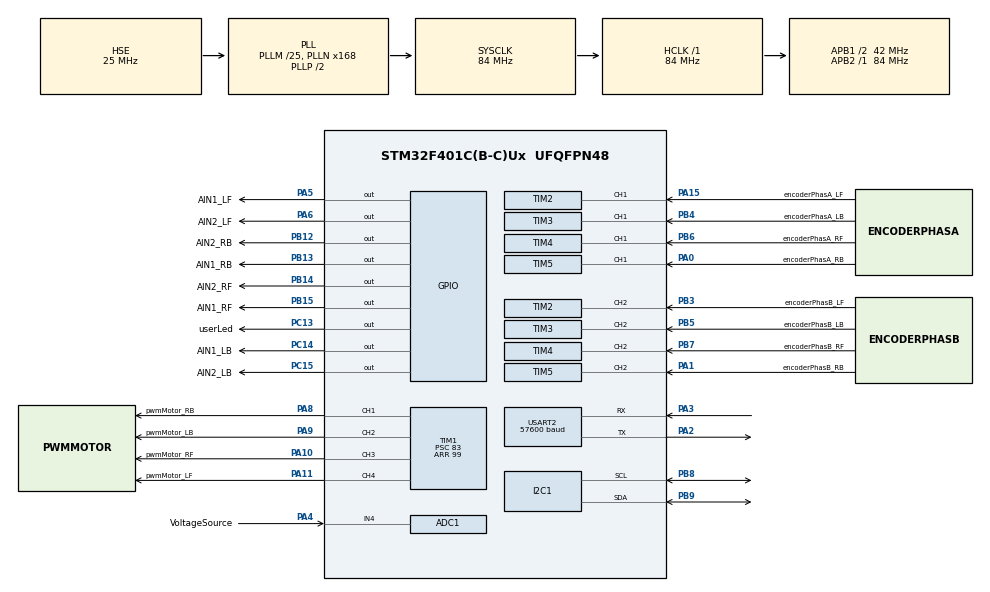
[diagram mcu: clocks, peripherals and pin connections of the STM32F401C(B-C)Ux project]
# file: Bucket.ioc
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ADC1.Channel-3\#ChannelRegularConversion=ADC_CHANNEL_4
ADC1.NbrOfConversionFlag=1
ADC1.Rank-3\#ChannelRegularConversion=1
ADC1.SamplingTime-3\#ChannelRegularConversion=ADC_SAMPLETIME_3CYCLES
ADC1.ScanConvMode=DISABLE
ADC1.master=1
I2C1.DualAddressMode=I2C_DUALADDRESS_DISABLE
Mcu.Family=STM32F4
Mcu.Name=STM32F401C(B-C)Ux
Mcu.Package=UFQFPN48
NVIC.PriorityGroup=NVIC_PRIORITYGROUP_4
NVIC.TIM1_UP_TIM10_IRQn=true\:0\:0\:false\:false\:true\:true\:true\:true
NVIC.USART2_IRQn=true\:0\:0\:false\:false\:true\:true\:true\:true
PA0-WKUP.GPIO_Label=encoderPhasA_RB
PA0-WKUP.Signal=S_TIM5_CH1
PA1.GPIO_Label=encoderPhasB_RB
PA1.Signal=S_TIM5_CH2
PA10.GPIO_Label=pwmMotor_RF
PA10.Signal=S_TIM1_CH3
PA11.GPIO_Label=pwmMotor_LF
PA11.Signal=S_TIM1_CH4
PA13.Mode=Serial_Wire
PA13.Signal=SYS_JTMS-SWDIO
PA14.Mode=Serial_Wire
PA14.Signal=SYS_JTCK-SWCLK
PA15.GPIO_Label=encoderPhasA_LF
PA15.Signal=S_TIM2_CH1_ETR
PA2.Mode=Asynchronous
PA2.Signal=USART2_TX
PA3.Mode=Asynchronous
PA3.Signal=USART2_RX
PA4.GPIO_Label=VoltageSource
PA4.Signal=ADCx_IN4
PA5.GPIO_Label=AIN1_LF
PA5.Signal=GPIO_Output
PA6.GPIO_Label=AIN2_LF
PA6.Signal=GPIO_Output
PA8.GPIO_Label=pwmMotor_RB
PA8.Signal=S_TIM1_CH1
PA9.GPIO_Label=pwmMotor_LB
PA9.Signal=S_TIM1_CH2
PB12.GPIO_Label=AIN2_RB
PB12.Signal=GPIO_Output
PB13.GPIO_Label=AIN1_RB
PB13.Signal=GPIO_Output
PB14.GPIO_Label=AIN2_RF
PB14.Signal=GPIO_Output
PB15.GPIO_Label=AIN1_RF
PB15.Signal=GPIO_Output
PB3.GPIO_Label=encoderPhasB_LF
PB3.Signal=S_TIM2_CH2
PB4.GPIO_Label=encoderPhasA_LB
PB4.Signal=S_TIM3_CH1
PB5.GPIO_Label=encoderPhasB_LB
PB5.Signal=S_TIM3_CH2
PB6.GPIO_Label=encoderPhasA_RF
PB6.Signal=S_TIM4_CH1
PB7.GPIO_Label=encoderPhasB_RF
PB7.Signal=S_TIM4_CH2
PB8.Mode=I2C
PB8.Signal=I2C1_SCL
PB9.Mode=I2C
PB9.Signal=I2C1_SDA
PC13-ANTI_TAMP.GPIO_Label=userLed
PC13-ANTI_TAMP.Signal=GPIO_Output
PC14-OSC32_IN.GPIO_Label=AIN1_LB
PC14-OSC32_IN.Signal=GPIO_Output
PC15-OSC32_OUT.GPIO_Label=AIN2_LB
PC15-OSC32_OUT.Signal=GPIO_Output
PH0\ -\ OSC_IN.Mode=HSE-External-Oscillator
PH0\ -\ OSC_IN.Signal=RCC_OSC_IN
PH1\ -\ OSC_OUT.Mode=HSE-External-Oscillator
PH1\ -\ OSC_OUT.Signal=RCC_OSC_OUT
ProjectManager.HeapSize=0x200
ProjectManager.StackSize=0x400
ProjectManager.TargetToolchain=STM32CubeIDE
RCC.48MHZClocksFreq_Value=42000000
RCC.AHBFreq_Value=84000000
RCC.APB1CLKDivider=RCC_HCLK_DIV2
RCC.APB1Freq_Value=42000000
RCC.APB1TimFreq_Value=84000000
RCC.APB2Freq_Value=84000000
RCC.APB2TimFreq_Value=84000000
RCC.CortexFreq_Value=84000000
RCC.HCLKFreq_Value=84000000
RCC.HSE_VALUE=25000000
RCC.HSI_VALUE=16000000
RCC.LSE_VALUE=32768
RCC.PLLM=25
RCC.PLLN=168
RCC.PLLSourceVirtual=RCC_PLLSOURCE_HSE
RCC.SYSCLKFreq_VALUE=84000000
RCC.SYSCLKSource=RCC_SYSCLKSOURCE_PLLCLK
RCC.VCOOutputFreq_Value=168000000
SH.ADCx_IN4.0=ADC1_IN4,IN4
SH.S_TIM1_CH1.0=TIM1_CH1,PWM Generation1 CH1
SH.S_TIM1_CH2.0=TIM1_CH2,PWM Generation2 CH2
SH.S_TIM1_CH3.0=TIM1_CH3,PWM Generation3 CH3
SH.S_TIM1_CH4.0=TIM1_CH4,PWM Generation4 CH4
SH.S_TIM2_CH1_ETR.0=TIM2_CH1,Encoder_Interface
SH.S_TIM2_CH2.0=TIM2_CH2,Encoder_Interface
SH.S_TIM3_CH1.0=TIM3_CH1,Encoder_Interface
SH.S_TIM3_CH2.0=TIM3_CH2,Encoder_Interface
SH.S_TIM4_CH1.0=TIM4_CH1,Encoder_Interface
SH.S_TIM4_CH2.0=TIM4_CH2,Encoder_Interface
SH.S_TIM5_CH1.0=TIM5_CH1,Encoder_Interface
SH.S_TIM5_CH2.0=TIM5_CH2,Encoder_Interface
TIM1.AutoReloadPreload=TIM_AUTORELOAD_PRELOAD_ENABLE
TIM1.BreakPolarity=TIM_BREAKPOLARITY_HIGH
TIM1.Channel-PWM\ Generation1\ CH1=TIM_CHANNEL_1
TIM1.Channel-PWM\ Generation2\ CH2=TIM_CHANNEL_2
TIM1.Channel-PWM\ Generation3\ CH3=TIM_CHANNEL_3
TIM1.Channel-PWM\ Generation4\ CH4=TIM_CHANNEL_4
TIM1.OCPolarity_1=TIM_OCPOLARITY_HIGH
TIM1.OCPolarity_3=TIM_OCPOLARITY_HIGH
TIM1.Period=99
TIM1.Prescaler=83
TIM1.Pulse-PWM\ Generation1\ CH1=0
TIM1.Pulse-PWM\ Generation2\ CH2=0
TIM1.Pulse-PWM\ Generation3\ CH3=0
TIM1.Pulse-PWM\ Generation4\ CH4=0
TIM10.AutoReloadPreload=TIM_AUTORELOAD_PRELOAD_ENABLE
TIM10.Period=9999
TIM10.Prescaler=83
TIM2.EncoderMode=TIM_ENCODERMODE_TI12
TIM2.IC1Filter=1
TIM2.IC2Filter=1
TIM3.EncoderMode=TIM_ENCODERMODE_TI12
TIM3.IC1Filter=1
TIM3.IC2Filter=1
TIM4.EncoderMode=TIM_ENCODERMODE_TI12
TIM4.IC1Filter=1
TIM4.IC2Filter=1
TIM5.EncoderMode=TIM_ENCODERMODE_TI12
TIM5.IC1Filter=1
TIM5.IC2Filter=1
USART2.BaudRate=57600
USART2.VirtualMode=VM_ASYNC
VP_TIM10_VS_ClockSourceINT.Mode=Enable_Timer
VP_TIM1_VS_ClockSourceINT.Mode=Internal
VP_TIM9_VS_ClockSourceINT.Mode=Internal
board=custom

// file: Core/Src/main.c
/* USER CODE BEGIN Header */
/**
 ******************************************************************************
 * @file           : main.c
 * @brief          : Main program body
 ******************************************************************************
 * @attention
 *
 * Copyright (c) 2026 STMicroelectronics.
 * All rights reserved.
 *
 * This software is licensed under terms that can be found in the LICENSE file
 * in the root directory of this software component.
 * If no LICENSE file comes with this software, it is provided AS-IS.
 *
 ******************************************************************************
 */
/* USER CODE END Header */
#include "main.h"

/* USER CODE BEGIN Includes */
#include "cpp_main.hpp"
/* USER CODE END Includes */

ADC_HandleTypeDef hadc1;

I2C_HandleTypeDef hi2c1;

TIM_HandleTypeDef htim1;
TIM_HandleTypeDef htim2;
TIM_HandleTypeDef htim3;
TIM_HandleTypeDef htim4;
TIM_HandleTypeDef htim5;
TIM_HandleTypeDef htim9;
TIM_HandleTypeDef htim10;

UART_HandleTypeDef huart2;

void SystemClock_Config(void);
static void MX_GPIO_Init(void);
static void MX_TIM1_Init(void);
static void MX_TIM3_Init(void);
static void MX_TIM4_Init(void);
static void MX_TIM5_Init(void);
static void MX_USART2_UART_Init(void);
static void MX_TIM10_Init(void);
static void MX_TIM2_Init(void);
static void MX_TIM9_Init(void);
static void MX_I2C1_Init(void);
static void MX_ADC1_Init(void);

int main(void)
{

  /* MCU Configuration--------------------------------------------------------*/

  /* Reset of all peripherals, Initializes the Flash interface and the Systick. */
  HAL_Init();

  /* Configure the system clock */
  SystemClock_Config();

  /* Initialize all configured peripherals */
  MX_GPIO_Init();
  MX_TIM1_Init();
  MX_TIM3_Init();
  MX_TIM4_Init();
  MX_TIM5_Init();
  MX_USART2_UART_Init();
  MX_TIM10_Init();
  MX_TIM2_Init();
  MX_TIM9_Init();
  MX_I2C1_Init();
  MX_ADC1_Init();
  /* USER CODE BEGIN 2 */

  cpp_main();   // Вызываем C++-функцию
  /* USER CODE END 2 */

  /* Infinite loop */
	while (1) {

	}
}

void SystemClock_Config(void)
{
  RCC_OscInitTypeDef RCC_OscInitStruct = {0};
  RCC_ClkInitTypeDef RCC_ClkInitStruct = {0};

  /** Configure the main internal regulator output voltage
  */
  __HAL_RCC_PWR_CLK_ENABLE();
  __HAL_PWR_VOLTAGESCALING_CONFIG(PWR_REGULATOR_VOLTAGE_SCALE2);

  /** Initializes the RCC Oscillators according to the specified parameters
  * in the RCC_OscInitTypeDef structure.
  */
  RCC_OscInitStruct.OscillatorType = RCC_OSCILLATORTYPE_HSE;
  RCC_OscInitStruct.HSEState = RCC_HSE_ON;
  RCC_OscInitStruct.PLL.PLLState = RCC_PLL_ON;
  RCC_OscInitStruct.PLL.PLLSource = RCC_PLLSOURCE_HSE;
  RCC_OscInitStruct.PLL.PLLM = 25;
  RCC_OscInitStruct.PLL.PLLN = 168;
  RCC_OscInitStruct.PLL.PLLP = RCC_PLLP_DIV2;
  RCC_OscInitStruct.PLL.PLLQ = 4;
  if (HAL_RCC_OscConfig(&RCC_OscInitStruct) != HAL_OK)
  {
    Error_Handler();
  }

  /** Initializes the CPU, AHB and APB buses clocks
  */
  RCC_ClkInitStruct.ClockType = RCC_CLOCKTYPE_HCLK|RCC_CLOCKTYPE_SYSCLK
                              |RCC_CLOCKTYPE_PCLK1|RCC_CLOCKTYPE_PCLK2;
  RCC_ClkInitStruct.SYSCLKSource = RCC_SYSCLKSOURCE_PLLCLK;
  RCC_ClkInitStruct.AHBCLKDivider = RCC_SYSCLK_DIV1;
  RCC_ClkInitStruct.APB1CLKDivider = RCC_HCLK_DIV2;
  RCC_ClkInitStruct.APB2CLKDivider = RCC_HCLK_DIV1;

  if (HAL_RCC_ClockConfig(&RCC_ClkInitStruct, FLASH_LATENCY_2) != HAL_OK)
  {
    Error_Handler();
  }
}

static void MX_ADC1_Init(void)
{

  ADC_ChannelConfTypeDef sConfig = {0};

  /** Configure the global features of the ADC (Clock, Resolution, Data Alignment and number of conversion)
  */
  hadc1.Instance = ADC1;
  hadc1.Init.ClockPrescaler = ADC_CLOCK_SYNC_PCLK_DIV4;
  hadc1.Init.Resolution = ADC_RESOLUTION_12B;
  hadc1.Init.ScanConvMode = DISABLE;
  hadc1.Init.ContinuousConvMode = DISABLE;
  hadc1.Init.DiscontinuousConvMode = DISABLE;
  hadc1.Init.ExternalTrigConvEdge = ADC_EXTERNALTRIGCONVEDGE_NONE;
  hadc1.Init.ExternalTrigConv = ADC_SOFTWARE_START;
  hadc1.Init.DataAlign = ADC_DATAALIGN_RIGHT;
  hadc1.Init.NbrOfConversion = 1;
  hadc1.Init.DMAContinuousRequests = DISABLE;
  hadc1.Init.EOCSelection = ADC_EOC_SINGLE_CONV;
  if (HAL_ADC_Init(&hadc1) != HAL_OK)
  {
    Error_Handler();
  }

  /** Configure for the selected ADC regular channel its corresponding rank in the sequencer and its sample time.
  */
  sConfig.Channel = ADC_CHANNEL_4;
  sConfig.Rank = 1;
  sConfig.SamplingTime = ADC_SAMPLETIME_3CYCLES;
  if (HAL_ADC_ConfigChannel(&hadc1, &sConfig) != HAL_OK)
  {
    Error_Handler();
  }

}

static void MX_I2C1_Init(void)
{

  hi2c1.Instance = I2C1;
  hi2c1.Init.ClockSpeed = 100000;
  hi2c1.Init.DutyCycle = I2C_DUTYCYCLE_2;
  hi2c1.Init.OwnAddress1 = 0;
  hi2c1.Init.AddressingMode = I2C_ADDRESSINGMODE_7BIT;
  hi2c1.Init.DualAddressMode = I2C_DUALADDRESS_DISABLE;
  hi2c1.Init.OwnAddress2 = 0;
  hi2c1.Init.GeneralCallMode = I2C_GENERALCALL_DISABLE;
  hi2c1.Init.NoStretchMode = I2C_NOSTRETCH_DISABLE;
  if (HAL_I2C_Init(&hi2c1) != HAL_OK)
  {
    Error_Handler();
  }

}

static void MX_TIM1_Init(void)
{

  TIM_ClockConfigTypeDef sClockSourceConfig = {0};
  TIM_MasterConfigTypeDef sMasterConfig = {0};
  TIM_OC_InitTypeDef sConfigOC = {0};
  TIM_BreakDeadTimeConfigTypeDef sBreakDeadTimeConfig = {0};

  htim1.Instance = TIM1;
  htim1.Init.Prescaler = 83;
  htim1.Init.CounterMode = TIM_COUNTERMODE_UP;
  htim1.Init.Period = 99;
  htim1.Init.ClockDivision = TIM_CLOCKDIVISION_DIV1;
  htim1.Init.RepetitionCounter = 0;
  htim1.Init.AutoReloadPreload = TIM_AUTORELOAD_PRELOAD_ENABLE;
  if (HAL_TIM_Base_Init(&htim1) != HAL_OK)
  {
    Error_Handler();
  }
  sClockSourceConfig.ClockSource = TIM_CLOCKSOURCE_INTERNAL;
  if (HAL_TIM_ConfigClockSource(&htim1, &sClockSourceConfig) != HAL_OK)
  {
    Error_Handler();
  }
  if (HAL_TIM_PWM_Init(&htim1) != HAL_OK)
  {
    Error_Handler();
  }
  sMasterConfig.MasterOutputTrigger = TIM_TRGO_RESET;
  sMasterConfig.MasterSlaveMode = TIM_MASTERSLAVEMODE_DISABLE;
  if (HAL_TIMEx_MasterConfigSynchronization(&htim1, &sMasterConfig) != HAL_OK)
  {
    Error_Handler();
  }
  sConfigOC.OCMode = TIM_OCMODE_PWM1;
  sConfigOC.Pulse = 0;
  sConfigOC.OCPolarity = TIM_OCPOLARITY_HIGH;
  sConfigOC.OCNPolarity = TIM_OCNPOLARITY_HIGH;
  sConfigOC.OCFastMode = TIM_OCFAST_DISABLE;
  sConfigOC.OCIdleState = TIM_OCIDLESTATE_RESET;
  sConfigOC.OCNIdleState = TIM_OCNIDLESTATE_RESET;
  if (HAL_TIM_PWM_ConfigChannel(&htim1, &sConfigOC, TIM_CHANNEL_1) != HAL_OK)
  {
    Error_Handler();
  }
  if (HAL_TIM_PWM_ConfigChannel(&htim1, &sConfigOC, TIM_CHANNEL_2) != HAL_OK)
  {
    Error_Handler();
  }
  if (HAL_TIM_PWM_ConfigChannel(&htim1, &sConfigOC, TIM_CHANNEL_3) != HAL_OK)
  {
    Error_Handler();
  }
  if (HAL_TIM_PWM_ConfigChannel(&htim1, &sConfigOC, TIM_CHANNEL_4) != HAL_OK)
  {
    Error_Handler();
  }
  sBreakDeadTimeConfig.OffStateRunMode = TIM_OSSR_DISABLE;
  sBreakDeadTimeConfig.OffStateIDLEMode = TIM_OSSI_DISABLE;
  sBreakDeadTimeConfig.LockLevel = TIM_LOCKLEVEL_OFF;
  sBreakDeadTimeConfig.DeadTime = 0;
  sBreakDeadTimeConfig.BreakState = TIM_BREAK_DISABLE;
  sBreakDeadTimeConfig.BreakPolarity = TIM_BREAKPOLARITY_HIGH;
  sBreakDeadTimeConfig.AutomaticOutput = TIM_AUTOMATICOUTPUT_DISABLE;
  if (HAL_TIMEx_ConfigBreakDeadTime(&htim1, &sBreakDeadTimeConfig) != HAL_OK)
  {
    Error_Handler();
  }
  HAL_TIM_MspPostInit(&htim1);

}

static void MX_TIM2_Init(void)
{

  TIM_Encoder_InitTypeDef sConfig = {0};
  TIM_MasterConfigTypeDef sMasterConfig = {0};

  htim2.Instance = TIM2;
  htim2.Init.Prescaler = 0;
  htim2.Init.CounterMode = TIM_COUNTERMODE_UP;
  htim2.Init.Period = 4294967295;
  htim2.Init.ClockDivision = TIM_CLOCKDIVISION_DIV1;
  htim2.Init.AutoReloadPreload = TIM_AUTORELOAD_PRELOAD_DISABLE;
  sConfig.EncoderMode = TIM_ENCODERMODE_TI12;
  sConfig.IC1Polarity = TIM_ICPOLARITY_RISING;
  sConfig.IC1Selection = TIM_ICSELECTION_DIRECTTI;
  sConfig.IC1Prescaler = TIM_ICPSC_DIV1;
  sConfig.IC1Filter = 1;
  sConfig.IC2Polarity = TIM_ICPOLARITY_RISING;
  sConfig.IC2Selection = TIM_ICSELECTION_DIRECTTI;
  sConfig.IC2Prescaler = TIM_ICPSC_DIV1;
  sConfig.IC2Filter = 1;
  if (HAL_TIM_Encoder_Init(&htim2, &sConfig) != HAL_OK)
  {
    Error_Handler();
  }
  sMasterConfig.MasterOutputTrigger = TIM_TRGO_RESET;
  sMasterConfig.MasterSlaveMode = TIM_MASTERSLAVEMODE_DISABLE;
  if (HAL_TIMEx_MasterConfigSynchronization(&htim2, &sMasterConfig) != HAL_OK)
  {
    Error_Handler();
  }

}

static void MX_TIM3_Init(void)
{

  TIM_Encoder_InitTypeDef sConfig = {0};
  TIM_MasterConfigTypeDef sMasterConfig = {0};

  htim3.Instance = TIM3;
  htim3.Init.Prescaler = 0;
  htim3.Init.CounterMode = TIM_COUNTERMODE_UP;
  htim3.Init.Period = 65535;
  htim3.Init.ClockDivision = TIM_CLOCKDIVISION_DIV1;
  htim3.Init.AutoReloadPreload = TIM_AUTORELOAD_PRELOAD_DISABLE;
  sConfig.EncoderMode = TIM_ENCODERMODE_TI12;
  sConfig.IC1Polarity = TIM_ICPOLARITY_RISING;
  sConfig.IC1Selection = TIM_ICSELECTION_DIRECTTI;
  sConfig.IC1Prescaler = TIM_ICPSC_DIV1;
  sConfig.IC1Filter = 1;
  sConfig.IC2Polarity = TIM_ICPOLARITY_RISING;
  sConfig.IC2Selection = TIM_ICSELECTION_DIRECTTI;
  sConfig.IC2Prescaler = TIM_ICPSC_DIV1;
  sConfig.IC2Filter = 1;
  if (HAL_TIM_Encoder_Init(&htim3, &sConfig) != HAL_OK)
  {
    Error_Handler();
  }
  sMasterConfig.MasterOutputTrigger = TIM_TRGO_RESET;
  sMasterConfig.MasterSlaveMode = TIM_MASTERSLAVEMODE_DISABLE;
  if (HAL_TIMEx_MasterConfigSynchronization(&htim3, &sMasterConfig) != HAL_OK)
  {
    Error_Handler();
  }

}

static void MX_TIM4_Init(void)
{

  TIM_Encoder_InitTypeDef sConfig = {0};
  TIM_MasterConfigTypeDef sMasterConfig = {0};

  htim4.Instance = TIM4;
  htim4.Init.Prescaler = 0;
  htim4.Init.CounterMode = TIM_COUNTERMODE_UP;
  htim4.Init.Period = 65535;
  htim4.Init.ClockDivision = TIM_CLOCKDIVISION_DIV1;
  htim4.Init.AutoReloadPreload = TIM_AUTORELOAD_PRELOAD_DISABLE;
  sConfig.EncoderMode = TIM_ENCODERMODE_TI12;
  sConfig.IC1Polarity = TIM_ICPOLARITY_RISING;
  sConfig.IC1Selection = TIM_ICSELECTION_DIRECTTI;
  sConfig.IC1Prescaler = TIM_ICPSC_DIV1;
  sConfig.IC1Filter = 1;
  sConfig.IC2Polarity = TIM_ICPOLARITY_RISING;
  sConfig.IC2Selection = TIM_ICSELECTION_DIRECTTI;
  sConfig.IC2Prescaler = TIM_ICPSC_DIV1;
  sConfig.IC2Filter = 1;
  if (HAL_TIM_Encoder_Init(&htim4, &sConfig) != HAL_OK)
  {
    Error_Handler();
  }
  sMasterConfig.MasterOutputTrigger = TIM_TRGO_RESET;
  sMasterConfig.MasterSlaveMode = TIM_MASTERSLAVEMODE_DISABLE;
  if (HAL_TIMEx_MasterConfigSynchronization(&htim4, &sMasterConfig) != HAL_OK)
  {
    Error_Handler();
  }

}

static void MX_TIM5_Init(void)
{

  TIM_Encoder_InitTypeDef sConfig = {0};
  TIM_MasterConfigTypeDef sMasterConfig = {0};

  htim5.Instance = TIM5;
  htim5.Init.Prescaler = 0;
  htim5.Init.CounterMode = TIM_COUNTERMODE_UP;
  htim5.Init.Period = 4294967295;
  htim5.Init.ClockDivision = TIM_CLOCKDIVISION_DIV1;
  htim5.Init.AutoReloadPreload = TIM_AUTORELOAD_PRELOAD_DISABLE;
  sConfig.EncoderMode = TIM_ENCODERMODE_TI12;
  sConfig.IC1Polarity = TIM_ICPOLARITY_RISING;
  sConfig.IC1Selection = TIM_ICSELECTION_DIRECTTI;
  sConfig.IC1Prescaler = TIM_ICPSC_DIV1;
  sConfig.IC1Filter = 1;
  sConfig.IC2Polarity = TIM_ICPOLARITY_RISING;
  sConfig.IC2Selection = TIM_ICSELECTION_DIRECTTI;
  sConfig.IC2Prescaler = TIM_ICPSC_DIV1;
  sConfig.IC2Filter = 1;
  if (HAL_TIM_Encoder_Init(&htim5, &sConfig) != HAL_OK)
  {
    Error_Handler();
  }
  sMasterConfig.MasterOutputTrigger = TIM_TRGO_RESET;
  sMasterConfig.MasterSlaveMode = TIM_MASTERSLAVEMODE_DISABLE;
  if (HAL_TIMEx_MasterConfigSynchronization(&htim5, &sMasterConfig) != HAL_OK)
  {
    Error_Handler();
  }

}

static void MX_TIM9_Init(void)
{

  TIM_ClockConfigTypeDef sClockSourceConfig = {0};

  htim9.Instance = TIM9;
  htim9.Init.Prescaler = 0;
  htim9.Init.CounterMode = TIM_COUNTERMODE_UP;
  htim9.Init.Period = 65535;
  htim9.Init.ClockDivision = TIM_CLOCKDIVISION_DIV1;
  htim9.Init.AutoReloadPreload = TIM_AUTORELOAD_PRELOAD_DISABLE;
  if (HAL_TIM_Base_Init(&htim9) != HAL_OK)
  {
    Error_Handler();
  }
  sClockSourceConfig.ClockSource = TIM_CLOCKSOURCE_INTERNAL;
  if (HAL_TIM_ConfigClockSource(&htim9, &sClockSourceConfig) != HAL_OK)
  {
    Error_Handler();
  }

}

static void MX_TIM10_Init(void)
{

  htim10.Instance = TIM10;
  htim10.Init.Prescaler = 83;
  htim10.Init.CounterMode = TIM_COUNTERMODE_UP;
  htim10.Init.Period = 9999;
  htim10.Init.ClockDivision = TIM_CLOCKDIVISION_DIV1;
  htim10.Init.AutoReloadPreload = TIM_AUTORELOAD_PRELOAD_ENABLE;
  if (HAL_TIM_Base_Init(&htim10) != HAL_OK)
  {
    Error_Handler();
  }

}

static void MX_USART2_UART_Init(void)
{

  huart2.Instance = USART2;
  huart2.Init.BaudRate = 57600;
  huart2.Init.WordLength = UART_WORDLENGTH_8B;
  huart2.Init.StopBits = UART_STOPBITS_1;
  huart2.Init.Parity = UART_PARITY_NONE;
  huart2.Init.Mode = UART_MODE_TX_RX;
  huart2.Init.HwFlowCtl = UART_HWCONTROL_NONE;
  huart2.Init.OverSampling = UART_OVERSAMPLING_16;
  if (HAL_UART_Init(&huart2) != HAL_OK)
  {
    Error_Handler();
  }

}

static void MX_GPIO_Init(void)
{
  GPIO_InitTypeDef GPIO_InitStruct = {0};

  /* GPIO Ports Clock Enable */
  __HAL_RCC_GPIOC_CLK_ENABLE();
  __HAL_RCC_GPIOH_CLK_ENABLE();
  __HAL_RCC_GPIOA_CLK_ENABLE();
  __HAL_RCC_GPIOB_CLK_ENABLE();

  /*Configure GPIO pin Output Level */
  HAL_GPIO_WritePin(GPIOC, userLed_Pin|AIN1_LB_Pin|AIN2_LB_Pin, GPIO_PIN_RESET);

  /*Configure GPIO pin Output Level */
  HAL_GPIO_WritePin(GPIOA, AIN1_LF_Pin|AIN2_LF_Pin, GPIO_PIN_RESET);

  /*Configure GPIO pin Output Level */
  HAL_GPIO_WritePin(GPIOB, AIN2_RB_Pin|AIN1_RB_Pin|AIN2_RF_Pin|AIN1_RF_Pin, GPIO_PIN_RESET);

  /*Configure GPIO pins : userLed_Pin AIN1_LB_Pin AIN2_LB_Pin */
  GPIO_InitStruct.Pin = userLed_Pin|AIN1_LB_Pin|AIN2_LB_Pin;
  GPIO_InitStruct.Mode = GPIO_MODE_OUTPUT_PP;
  GPIO_InitStruct.Pull = GPIO_NOPULL;
  GPIO_InitStruct.Speed = GPIO_SPEED_FREQ_LOW;
  HAL_GPIO_Init(GPIOC, &GPIO_InitStruct);

  /*Configure GPIO pins : AIN1_LF_Pin AIN2_LF_Pin */
  GPIO_InitStruct.Pin = AIN1_LF_Pin|AIN2_LF_Pin;
  GPIO_InitStruct.Mode = GPIO_MODE_OUTPUT_PP;
  GPIO_InitStruct.Pull = GPIO_NOPULL;
  GPIO_InitStruct.Speed = GPIO_SPEED_FREQ_LOW;
  HAL_GPIO_Init(GPIOA, &GPIO_InitStruct);

  /*Configure GPIO pins : AIN2_RB_Pin AIN1_RB_Pin AIN2_RF_Pin AIN1_RF_Pin */
  GPIO_InitStruct.Pin = AIN2_RB_Pin|AIN1_RB_Pin|AIN2_RF_Pin|AIN1_RF_Pin;
  GPIO_InitStruct.Mode = GPIO_MODE_OUTPUT_PP;
  GPIO_InitStruct.Pull = GPIO_NOPULL;
  GPIO_InitStruct.Speed = GPIO_SPEED_FREQ_LOW;
  HAL_GPIO_Init(GPIOB, &GPIO_InitStruct);

}

void Error_Handler(void)
{
	__disable_irq();
	while (1) {
	}
}
